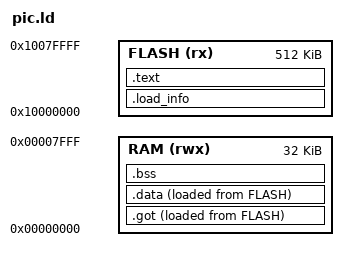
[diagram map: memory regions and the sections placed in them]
;/*
; * Copyright (c) 2018 ARM Limited
; *
; * Licensed under the Apache License, Version 2.0 (the "License");
; * you may not use this file except in compliance with the License.
; * You may obtain a copy of the License at
; *
; *     http://www.apache.org/licenses/LICENSE-2.0
; *
; * Unless required by applicable law or agreed to in writing, software
; * distributed under the License is distributed on an "AS IS" BASIS,
; * WITHOUT WARRANTIES OR CONDITIONS OF ANY KIND, either express or implied.
; * See the License for the specific language governing permissions and
; * limitations under the License.
; *
; *
; * This file is derivative of CMSIS V5.00 gcc_arm.ld
; */

/* Linker script to configure memory regions. */
/* This file will be run trough the pre-processor. */

MEMORY
{
  FLASH (rx)  : ORIGIN = 0x10000000, LENGTH = 0x00080000
  RAM   (rwx) : ORIGIN = 0x00000000, LENGTH = 0x00008000
}

SECTIONS
{
    .load_info :
    {
        KEEP(*(.load_info))
    } > FLASH

    .text :
    {
        _text = .;
        *(.text*)

        KEEP(*(.init))
        KEEP(*(.fini))

        *crtbegin.o(.ctors)
        *crtbegin?.o(.ctors)
        *(EXCLUDE_FILE(*crtend?.o *crtend.o) .ctors)
        *(SORT(.ctors.*))
        *(.ctors)

        *crtbegin.o(.dtors)
        *crtbegin?.o(.dtors)
        *(EXCLUDE_FILE(*crtend?.o *crtend.o) .dtors)
        *(SORT(.dtors.*))
        *(.dtors)

        *(.rodata*)
        _etext = .;
    } > FLASH

    .got :
    {
        _got = .;
        *(.got*)
        _egot = .;
        _plt = .;
        *(.got.plt*)
        _eplt = .;
    } > RAM AT > FLASH

    .data :
    {
        _data = .;
        *(vtable)
        *(.data*)

        . = ALIGN(4);
        PROVIDE_HIDDEN (__preinit_array_start = .);
        KEEP(*(.preinit_array))
        PROVIDE_HIDDEN (__preinit_array_end = .);

        . = ALIGN(4);
        PROVIDE_HIDDEN (__init_array_start = .);
        KEEP(*(SORT(.init_array.*)))
        KEEP(*(.init_array))
        PROVIDE_HIDDEN (__init_array_end = .);


        . = ALIGN(4);
        PROVIDE_HIDDEN (__fini_array_start = .);
        KEEP(*(SORT(.fini_array.*)))
        KEEP(*(.fini_array))
        PROVIDE_HIDDEN (__fini_array_end = .);

        KEEP(*(.jcr*))
        . = ALIGN(4);
        _edata = .;
    } > RAM AT > FLASH

    .bss :
    {
        . = ALIGN(4);
        _bss = .;
        *(.bss*)
        *(COMMON)
        . = ALIGN(4);
        _ebss = .;
    } > RAM
}
